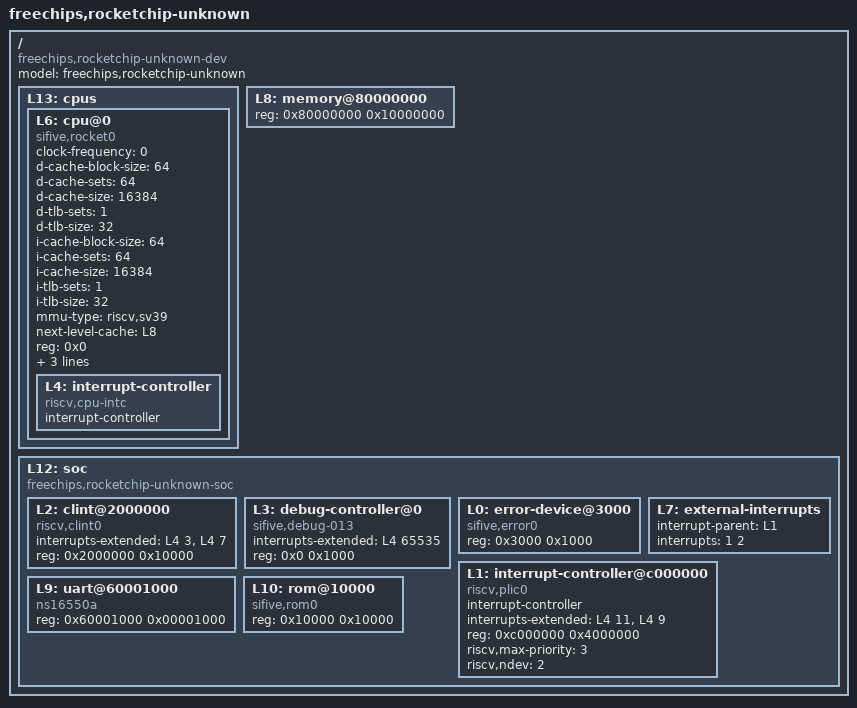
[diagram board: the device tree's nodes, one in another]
/dts-v1/;

/ {
	#address-cells = <1>;
	#size-cells = <1>;
	compatible = "freechips,rocketchip-unknown-dev";
	model = "freechips,rocketchip-unknown";
	L13: cpus {
		#address-cells = <1>;
		#size-cells = <0>;
		L6: cpu@0 {
			clock-frequency = <0>;
			compatible = "sifive,rocket0", "riscv";
			d-cache-block-size = <64>;
			d-cache-sets = <64>;
			d-cache-size = <16384>;
			d-tlb-sets = <1>;
			d-tlb-size = <32>;
			device_type = "cpu";
			i-cache-block-size = <64>;
			i-cache-sets = <64>;
			i-cache-size = <16384>;
			i-tlb-sets = <1>;
			i-tlb-size = <32>;
			mmu-type = "riscv,sv39";
			next-level-cache = <&L8>;
			reg = <0x0>;
			riscv,isa = "rv64imafdc";
			status = "okay";
			timebase-frequency = <1000000>;
			tlb-split;
			L4: interrupt-controller {
				#interrupt-cells = <1>;
				compatible = "riscv,cpu-intc";
				interrupt-controller;
			};
		};
	};
	L8: memory@80000000 {
		device_type = "memory";
		reg = <0x80000000 0x10000000>;
	};
	L12: soc {
		#address-cells = <1>;
		#size-cells = <1>;
		compatible = "freechips,rocketchip-unknown-soc", "simple-bus";
		ranges;
		L2: clint@2000000 {
			compatible = "riscv,clint0";
			interrupts-extended = <&L4 3 &L4 7>;
			reg = <0x2000000 0x10000>;
			reg-names = "control";
		};
		L3: debug-controller@0 {
			compatible = "sifive,debug-013", "riscv,debug-013";
			interrupts-extended = <&L4 65535>;
			reg = <0x0 0x1000>;
			reg-names = "control";
		};
		L0: error-device@3000 {
			compatible = "sifive,error0";
			reg = <0x3000 0x1000>;
		};
		L7: external-interrupts {
			interrupt-parent = <&L1>;
			interrupts = <1 2>;
		};
		L1: interrupt-controller@c000000 {
			#interrupt-cells = <1>;
			compatible = "riscv,plic0";
			interrupt-controller;
			interrupts-extended = <&L4 11 &L4 9>;
			reg = <0xc000000 0x4000000>;
			reg-names = "control";
			riscv,max-priority = <3>;
			riscv,ndev = <2>;
		};
		L9: uart@60001000 {
			compatible = "ns16550a";
			reg = <0x60001000 0x00001000>;
		};
		L10: rom@10000 {
			compatible = "sifive,rom0";
			reg = <0x10000 0x10000>;
			reg-names = "mem";
		};
	};
};
